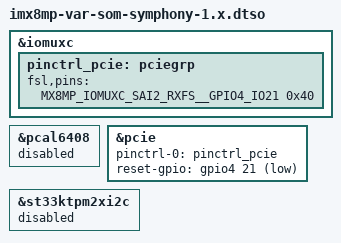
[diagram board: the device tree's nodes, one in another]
// SPDX-License-Identifier: (GPL-2.0+ OR MIT)
/*
 * Device tree overlay to support the VAR-SOM-MX8MP on Symphony Board 1.x
 *
 * Copyright 2025 Variscite Ltd.
 */

/dts-v1/;
/plugin/;

#include <dt-bindings/gpio/gpio.h>

#include "imx8mp-pinfunc.h"

&iomuxc {
	pinctrl_pcie: pciegrp {
		fsl,pins = <
			MX8MP_IOMUXC_SAI2_RXFS__GPIO4_IO21				0x40
		>;
	};
};

&pcal6408 {
	status = "disabled";
};

&pcie {
	pinctrl-names = "default";
	pinctrl-0 = <&pinctrl_pcie>;
	reset-gpio = <&gpio4 21 GPIO_ACTIVE_LOW>;
};

&st33ktpm2xi2c {
	status = "disabled";
};

